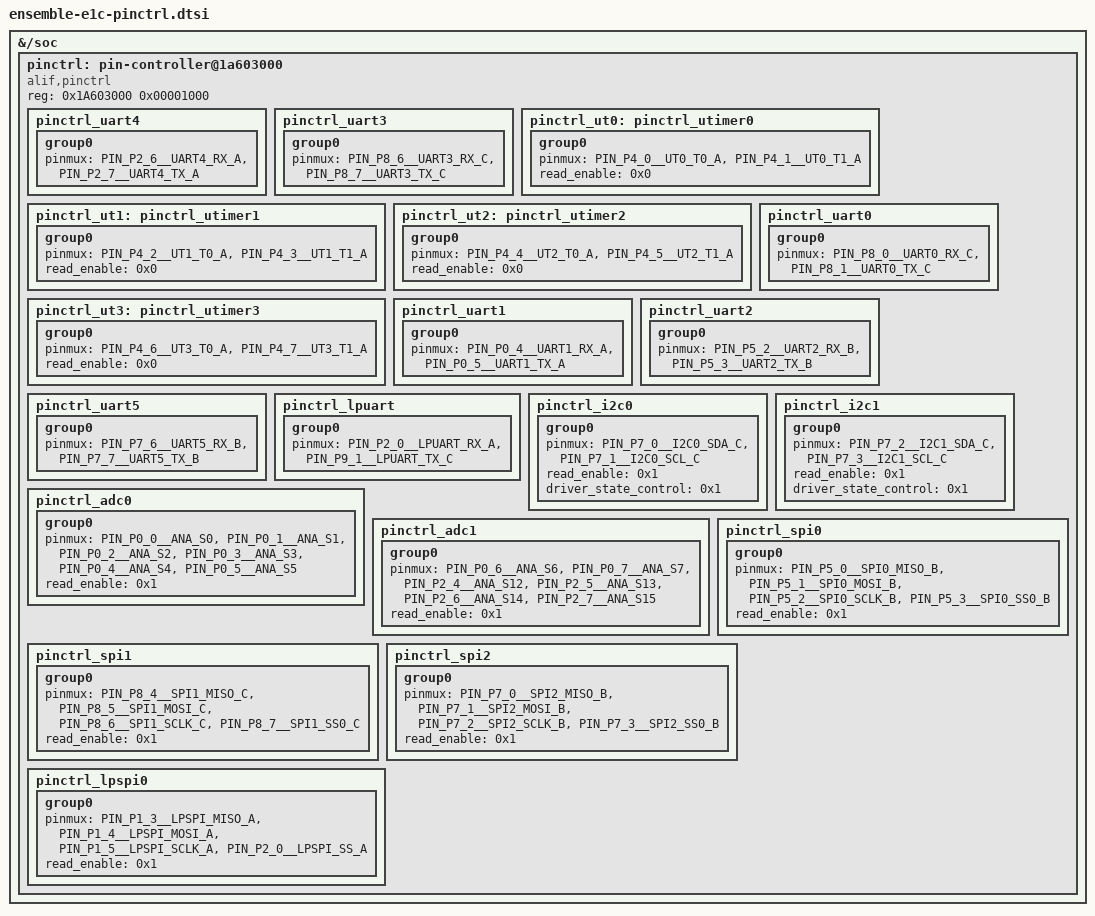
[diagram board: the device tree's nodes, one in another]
/* Copyright (c) 2024 Alif Semiconductor
 *
 * SPDX-License-Identifier: Apache-2.0
 */

#include <dt-bindings/pinctrl/ensemble-e1c-pinctrl.h>

&{/soc} {
	pinctrl: pin-controller@1a603000 {
		compatible = "alif,pinctrl";
		reg =   <0x1A603000 0x00001000>;
	};
};

&pinctrl {
	pinctrl_uart4: pinctrl_uart4 {
		group0 {
			pinmux = < PIN_P2_6__UART4_RX_A >,
				 < PIN_P2_7__UART4_TX_A >;
			/* pad config default values
			 * read_enable = < 0x1 >; 0 for disable, 1 for enable
			 * schmitt_enable = < 0x1 >; 0x0 for disable
			 *			  0x1 for enable
			 * slew_rate = < 0x0 > ; 0 for slow, 1 for fast
			 * driver_state_control = <0>;
			 *			0 for high z
			 *			1 for pull up
			 *			2 for pull down
			 *			3 for bus repeater
			 * drive_strength = <4>;
			 *			2 for 2mA
			 *			4 for 4mA
			 *			8 for 8mA
			 *			12 for 12mA
			 * driver = < 0x0 >; 0 for push pull, 1 for open drain
			 */
		};
	};

	pinctrl_uart3: pinctrl_uart3 {
		group0 {
			pinmux = < PIN_P8_6__UART3_RX_C >,
				 < PIN_P8_7__UART3_TX_C >;
		};
	};

	pinctrl_ut0: pinctrl_utimer0 {
		group0 {
			pinmux = < PIN_P4_0__UT0_T0_A >,
				 < PIN_P4_1__UT0_T1_A >;
			read_enable = < 0x0 >;
		};
	};

	pinctrl_ut1: pinctrl_utimer1 {
		group0 {
			pinmux = < PIN_P4_2__UT1_T0_A >,
				 < PIN_P4_3__UT1_T1_A >;
			read_enable = < 0x0 >;
		};
	};

	pinctrl_ut2: pinctrl_utimer2 {
		group0 {
			pinmux = < PIN_P4_4__UT2_T0_A >,
				 < PIN_P4_5__UT2_T1_A >;
			read_enable = < 0x0 >;
		};
	};

	pinctrl_ut3: pinctrl_utimer3 {
		group0 {
			pinmux = < PIN_P4_6__UT3_T0_A >,
				 < PIN_P4_7__UT3_T1_A >;
			read_enable = < 0x0 >;
		};
	};

	pinctrl_uart0: pinctrl_uart0 {
		group0 {
			pinmux = < PIN_P8_0__UART0_RX_C >,
				 < PIN_P8_1__UART0_TX_C >;
		};
	};

	pinctrl_uart1: pinctrl_uart1 {
		group0 {
			pinmux = < PIN_P0_4__UART1_RX_A >,
				 < PIN_P0_5__UART1_TX_A >;
		};
	};

	pinctrl_uart2: pinctrl_uart2 {
		group0 {
			pinmux = < PIN_P5_2__UART2_RX_B >,
				 < PIN_P5_3__UART2_TX_B >;
		};
	};

	pinctrl_uart5: pinctrl_uart5 {
		group0 {
			pinmux = < PIN_P7_6__UART5_RX_B >,
				 < PIN_P7_7__UART5_TX_B >;
		};
	};

	pinctrl_lpuart: pinctrl_lpuart {
		group0 {
			pinmux = < PIN_P2_0__LPUART_RX_A >,
				 < PIN_P9_1__LPUART_TX_C >;
		};
	};

	pinctrl_i2c0: pinctrl_i2c0 {
		group0 {
			pinmux = < PIN_P7_0__I2C0_SDA_C >,
				 < PIN_P7_1__I2C0_SCL_C >;

			read_enable = < 0x1 >;
			driver_state_control = < 0x1 >;
		};
	};
	pinctrl_i2c1: pinctrl_i2c1 {
		group0 {
			pinmux = < PIN_P7_2__I2C1_SDA_C >,
				 < PIN_P7_3__I2C1_SCL_C >;
			read_enable = < 0x1 >;
			driver_state_control = < 0x1 >;
		};
	};

	pinctrl_adc0:pinctrl_adc0 {
		group0 {
			pinmux = <PIN_P0_0__ANA_S0>,
			<PIN_P0_1__ANA_S1>,
			<PIN_P0_2__ANA_S2>,
			<PIN_P0_3__ANA_S3>,
			<PIN_P0_4__ANA_S4>,
			<PIN_P0_5__ANA_S5>;
			read_enable = < 0x1 >;
		};
	};

	pinctrl_adc1:pinctrl_adc1 {
		group0 {
			pinmux = <PIN_P0_6__ANA_S6>,
			<PIN_P0_7__ANA_S7>,
			<PIN_P2_4__ANA_S12>,
			<PIN_P2_5__ANA_S13>,
			<PIN_P2_6__ANA_S14>,
			<PIN_P2_7__ANA_S15>;
			read_enable = < 0x1 >;
		};
	};

	pinctrl_spi0: pinctrl_spi0 {
		group0 {
			pinmux = < PIN_P5_0__SPI0_MISO_B >,
				 < PIN_P5_1__SPI0_MOSI_B >,
				 < PIN_P5_2__SPI0_SCLK_B >,
				 < PIN_P5_3__SPI0_SS0_B >;
			read_enable = < 0x1 >;
		};
	};
	pinctrl_spi1: pinctrl_spi1 {
		group0 {
			pinmux = < PIN_P8_4__SPI1_MISO_C >,
				 < PIN_P8_5__SPI1_MOSI_C >,
				 < PIN_P8_6__SPI1_SCLK_C >,
				 < PIN_P8_7__SPI1_SS0_C >;
			read_enable = < 0x1 >;
		};
	};
	pinctrl_spi2: pinctrl_spi2 {
		group0 {
			pinmux = < PIN_P7_0__SPI2_MISO_B >,
				 < PIN_P7_1__SPI2_MOSI_B >,
				 < PIN_P7_2__SPI2_SCLK_B >,
				 < PIN_P7_3__SPI2_SS0_B >;
			read_enable = < 0x1 >;
		};
	};
	pinctrl_lpspi0: pinctrl_lpspi0 {
		group0 {
			pinmux = < PIN_P1_3__LPSPI_MISO_A >,
				 < PIN_P1_4__LPSPI_MOSI_A >,
				 < PIN_P1_5__LPSPI_SCLK_A >,
				 < PIN_P2_0__LPSPI_SS_A >;
			read_enable = < 0x1 >;
		};
	};

};
